AUTOSAR XML (schema 00046)
package /ComponentTypes
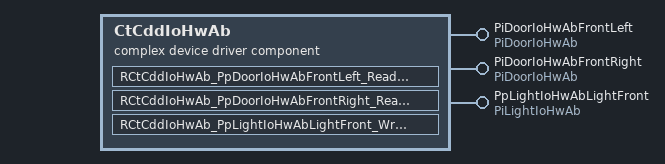
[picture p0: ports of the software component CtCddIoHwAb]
  complex device driver sw component type CtCddIoHwAb
    provide port PiDoorIoHwAbFrontLeft: server-com-spec{operation=ReadChannel, queue-length=1}, provided-interface=PiDoorIoHwAb
    provide port PiDoorIoHwAbFrontRight: server-com-spec{operation=ReadChannel, queue-length=1}, provided-interface=PiDoorIoHwAb
    provide port PpLightIoHwAbLightFront: server-com-spec{operation=WriteChannel, queue-length=1}, provided-interface=PiLightIoHwAb
    behavior CtCddIoHwAb_InternalBehavior
      operation invoked event OIT_PiDoorIoHwAbFrontLeft_ReadChannel_PiDoorIoHwAbFrontLeft_ReadChannel: start-on-event=RCtCddIoHwAb_PpDoorIoHwAbFrontLeft_ReadChannel, operation=PiDoorIoHwAbFrontLeft.ReadChannel
      operation invoked event OIT_PiDoorIoHwAbFrontRight_ReadChannel_PiDoorIoHwAbFrontRight_ReadChannel: start-on-event=RCtCddIoHwAb_PpDoorIoHwAbFrontRight_ReadChannel, operation=PiDoorIoHwAbFrontRight.ReadChannel
      operation invoked event OIT_PpLightIoHwAbLightFront_WriteChannel_PpLightIoHwAbLightFront_WriteChannel: start-on-event=RCtCddIoHwAb_PpLightIoHwAbLightFront_WriteChannel, operation=PpLightIoHwAbLightFront.WriteChannel
      runnable RCtCddIoHwAb_PpDoorIoHwAbFrontLeft_ReadChannel
      runnable RCtCddIoHwAb_PpDoorIoHwAbFrontRight_ReadChannel
      runnable RCtCddIoHwAb_PpLightIoHwAbLightFront_WriteChannel
  swc implementation CtCddIoHwAb_Implementation: behavior=CtCddIoHwAb_InternalBehavior
